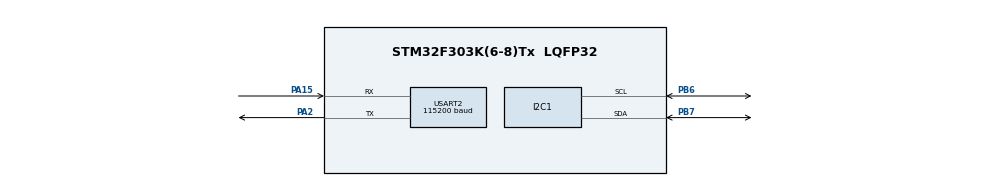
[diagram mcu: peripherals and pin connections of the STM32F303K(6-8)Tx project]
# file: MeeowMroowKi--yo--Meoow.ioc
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Dma.Request0=USART2_RX
Dma.Request1=USART2_TX
Dma.USART2_RX.0.Direction=DMA_PERIPH_TO_MEMORY
Dma.USART2_RX.0.Instance=DMA1_Channel6
Dma.USART2_RX.0.MemDataAlignment=DMA_MDATAALIGN_BYTE
Dma.USART2_RX.0.MemInc=DMA_MINC_ENABLE
Dma.USART2_RX.0.Mode=DMA_CIRCULAR
Dma.USART2_RX.0.PeriphDataAlignment=DMA_PDATAALIGN_BYTE
Dma.USART2_RX.0.PeriphInc=DMA_PINC_DISABLE
Dma.USART2_RX.0.Priority=DMA_PRIORITY_MEDIUM
Dma.USART2_TX.1.Direction=DMA_MEMORY_TO_PERIPH
Dma.USART2_TX.1.Instance=DMA1_Channel7
Dma.USART2_TX.1.MemDataAlignment=DMA_MDATAALIGN_BYTE
Dma.USART2_TX.1.MemInc=DMA_MINC_ENABLE
Dma.USART2_TX.1.Mode=DMA_NORMAL
Dma.USART2_TX.1.PeriphDataAlignment=DMA_PDATAALIGN_BYTE
Dma.USART2_TX.1.PeriphInc=DMA_PINC_DISABLE
Dma.USART2_TX.1.Priority=DMA_PRIORITY_MEDIUM
I2C1.OwnAddress=1
Mcu.Family=STM32F3
Mcu.Name=STM32F303K(6-8)Tx
Mcu.Package=LQFP32
NVIC.DMA1_Channel6_IRQn=true\:0\:0\:false\:false\:true\:false\:true\:true
NVIC.DMA1_Channel7_IRQn=true\:0\:0\:false\:false\:true\:false\:true\:true
NVIC.I2C1_EV_IRQn=true\:0\:0\:false\:false\:true\:true\:true\:true
NVIC.PriorityGroup=NVIC_PRIORITYGROUP_4
NVIC.USART2_IRQn=true\:0\:0\:false\:false\:true\:true\:true\:true
PA15.Mode=Asynchronous
PA15.Signal=USART2_RX
PA2.Mode=Asynchronous
PA2.Signal=USART2_TX
PB6.Mode=I2C
PB6.Signal=I2C1_SCL
PB7.Mode=I2C
PB7.Signal=I2C1_SDA
ProjectManager.HeapSize=0x200
ProjectManager.StackSize=0x400
ProjectManager.TargetToolchain=STM32CubeIDE
RCC.AHBFreq_Value=8000000
RCC.APB1Freq_Value=8000000
RCC.APB2Freq_Value=8000000
RCC.CortexFreq_Value=8000000
RCC.HSE_VALUE=8000000
RCC.HSI_VALUE=8000000
RCC.SYSCLKFreq_VALUE=8000000
USART2.BaudRate=115200
USART2.VirtualMode-Asynchronous=VM_ASYNC
board=custom

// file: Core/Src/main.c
/* USER CODE BEGIN Header */
/**
  ******************************************************************************
  * @file           : main.c
  * @brief          : Main program body
  ******************************************************************************
  * @attention
  *
  * Copyright (c) 2023 STMicroelectronics.
  * All rights reserved.
  *
  * This software is licensed under terms that can be found in the LICENSE file
  * in the root directory of this software component.
  * If no LICENSE file comes with this software, it is provided AS-IS.
  *
  ******************************************************************************
  */
/* USER CODE END Header */
#include "main.h"
#include "stm32f3xx_it.h"
#include "i2cm.h"
#include "tempSensor.h"
#include <string.h>

#include "../../LPS22HB/sensorPress.h"

void SystemClock_Config(void);
static void MX_GPIO_Init(void);
static void MX_DMA_Init(void);
static void MX_USART2_UART_Init(void);
static void MX_I2C1_Init(void);
void USART2_PutBuffer(uint8_t *buffer, uint8_t length);

/* USER CODE BEGIN 0 */
uint32_t bufferMeow[bufferSize];
uint32_t bufferMroow[bufferSize];
uint8_t bufferPaws[bufferSize];
uint32_t *dontPointAtMeMroow = bufferMroow;
/* USER CODE END 0 */

int main(void)
{

  /* MCU Configuration--------------------------------------------------------*/

  /* Reset of all peripherals, Initializes the Flash interface and the Systick. */
  LL_APB2_GRP1_EnableClock(LL_APB2_GRP1_PERIPH_SYSCFG);
  LL_APB1_GRP1_EnableClock(LL_APB1_GRP1_PERIPH_PWR);

  /* System interrupt init*/
  NVIC_SetPriorityGrouping(NVIC_PRIORITYGROUP_4);

  /* SysTick_IRQn interrupt configuration */
  NVIC_SetPriority(SysTick_IRQn, NVIC_EncodePriority(NVIC_GetPriorityGrouping(),15, 0));

  /* Configure the system clock */
  SystemClock_Config();

  /* Initialize all configured peripherals */
  MX_GPIO_Init();
  MX_DMA_Init();
  MX_USART2_UART_Init();
  MX_I2C1_Init();
  callBackFunction(readRegisterMeow,writeRegisterMroow);
  callBackFunctionLP(readRegisterMeow,writeRegisterMroow);
  htsInit();
  LL_mDelay(10);
  lpInit();
  LL_mDelay(10);
  //Activate_I2C1_IT();

  /* Infinite loop */
  while (1)
  {

	 /*
	  *
	  *  urob whoamI pre ten dalsi
	  *  kukni ako hladat data v nich
	  *  asi to bude podla registor... musis precitat pichoviny
	  *  a potom súravne registry pingovat to vse...
	  *
	  *
	  */
	  memset(bufferPaws, 0, bufferSize);
	  LL_mDelay(100);
	  double value = readTemp();
	  LL_mDelay(1);
	  double valueH = readHum();
	  LL_mDelay(1);
	  double valueP = readPress();
	  LL_mDelay(1);
	  double valueA = getAlt(valueP);
	  sprintf((char*)bufferPaws, "temp: %f[C], hum: %f[%%], press %f[hBar], vyska: %f[m] \n \r",value, valueH, valueP,valueA);
	  USART2_PutBuffer(bufferPaws, sizeof(bufferPaws));

	  LL_mDelay(500);
  }
}

void SystemClock_Config(void)
{
  LL_FLASH_SetLatency(LL_FLASH_LATENCY_0);
  while(LL_FLASH_GetLatency()!= LL_FLASH_LATENCY_0)
  {
  }
  LL_RCC_HSI_Enable();

   /* Wait till HSI is ready */
  while(LL_RCC_HSI_IsReady() != 1)
  {

  }
  LL_RCC_HSI_SetCalibTrimming(16);
  LL_RCC_SetAHBPrescaler(LL_RCC_SYSCLK_DIV_1);
  LL_RCC_SetAPB1Prescaler(LL_RCC_APB1_DIV_1);
  LL_RCC_SetAPB2Prescaler(LL_RCC_APB2_DIV_1);
  LL_RCC_SetSysClkSource(LL_RCC_SYS_CLKSOURCE_HSI);

   /* Wait till System clock is ready */
  while(LL_RCC_GetSysClkSource() != LL_RCC_SYS_CLKSOURCE_STATUS_HSI)
  {

  }
  LL_Init1msTick(8000000);
  LL_SetSystemCoreClock(8000000);
  LL_RCC_SetI2CClockSource(LL_RCC_I2C1_CLKSOURCE_HSI);
}

static void MX_I2C1_Init(void)
{

  LL_I2C_InitTypeDef I2C_InitStruct = {0};

  LL_GPIO_InitTypeDef GPIO_InitStruct = {0};

  LL_AHB1_GRP1_EnableClock(LL_AHB1_GRP1_PERIPH_GPIOB);
  /**I2C1 GPIO Configuration
  PB6   ------> I2C1_SCL
  PB7   ------> I2C1_SDA
  */
  GPIO_InitStruct.Pin = LL_GPIO_PIN_6|LL_GPIO_PIN_7;
  GPIO_InitStruct.Mode = LL_GPIO_MODE_ALTERNATE;
  GPIO_InitStruct.Speed = LL_GPIO_SPEED_FREQ_HIGH;
  GPIO_InitStruct.OutputType = LL_GPIO_OUTPUT_OPENDRAIN;
  GPIO_InitStruct.Pull = LL_GPIO_PULL_UP;
  GPIO_InitStruct.Alternate = LL_GPIO_AF_4;
  LL_GPIO_Init(GPIOB, &GPIO_InitStruct);

  /* Peripheral clock enable */
  LL_APB1_GRP1_EnableClock(LL_APB1_GRP1_PERIPH_I2C1);

  /* I2C1 interrupt Init */
  NVIC_SetPriority(I2C1_EV_IRQn, NVIC_EncodePriority(NVIC_GetPriorityGrouping(),0, 0));
  NVIC_EnableIRQ(I2C1_EV_IRQn);

  /** I2C Initialization
  */
  LL_I2C_EnableAutoEndMode(I2C1);
  LL_I2C_DisableOwnAddress2(I2C1);
  LL_I2C_DisableGeneralCall(I2C1);
  LL_I2C_EnableClockStretching(I2C1);
  I2C_InitStruct.PeripheralMode = LL_I2C_MODE_I2C;
  I2C_InitStruct.Timing = 0x2000090E;
  I2C_InitStruct.AnalogFilter = LL_I2C_ANALOGFILTER_ENABLE;
  I2C_InitStruct.DigitalFilter = 0;
  I2C_InitStruct.OwnAddress1 = 2;
  I2C_InitStruct.TypeAcknowledge = LL_I2C_ACK;
  I2C_InitStruct.OwnAddrSize = LL_I2C_OWNADDRESS1_7BIT;
  LL_I2C_Init(I2C1, &I2C_InitStruct);
  LL_I2C_SetOwnAddress2(I2C1, 0, LL_I2C_OWNADDRESS2_NOMASK);
  /* USER CODE BEGIN I2C1_Init 2 */
  LL_I2C_SetMode(I2C1, LL_I2C_MODE_I2C);
  //LL_I2C_Enable(I2C1);
  LL_I2C_Enable(I2C1);
  /* USER CODE END I2C1_Init 2 */

}

static void MX_USART2_UART_Init(void)
{

  LL_USART_InitTypeDef USART_InitStruct = {0};

  LL_GPIO_InitTypeDef GPIO_InitStruct = {0};

  /* Peripheral clock enable */
  LL_APB1_GRP1_EnableClock(LL_APB1_GRP1_PERIPH_USART2);

  LL_AHB1_GRP1_EnableClock(LL_AHB1_GRP1_PERIPH_GPIOA);
  /**USART2 GPIO Configuration
  PA2   ------> USART2_TX
  PA15   ------> USART2_RX
  */
  GPIO_InitStruct.Pin = LL_GPIO_PIN_2|LL_GPIO_PIN_15;
  GPIO_InitStruct.Mode = LL_GPIO_MODE_ALTERNATE;
  GPIO_InitStruct.Speed = LL_GPIO_SPEED_FREQ_HIGH;
  GPIO_InitStruct.OutputType = LL_GPIO_OUTPUT_PUSHPULL;
  GPIO_InitStruct.Pull = LL_GPIO_PULL_NO;
  GPIO_InitStruct.Alternate = LL_GPIO_AF_7;
  LL_GPIO_Init(GPIOA, &GPIO_InitStruct);

  /* USART2 DMA Init */

  /* USART2_RX Init */
  LL_DMA_SetDataTransferDirection(DMA1, LL_DMA_CHANNEL_6, LL_DMA_DIRECTION_PERIPH_TO_MEMORY);
  LL_DMA_SetChannelPriorityLevel(DMA1, LL_DMA_CHANNEL_6, LL_DMA_PRIORITY_MEDIUM);
  LL_DMA_SetMode(DMA1, LL_DMA_CHANNEL_6, LL_DMA_MODE_CIRCULAR);
  LL_DMA_SetPeriphIncMode(DMA1, LL_DMA_CHANNEL_6, LL_DMA_PERIPH_NOINCREMENT);
  LL_DMA_SetMemoryIncMode(DMA1, LL_DMA_CHANNEL_6, LL_DMA_MEMORY_INCREMENT);
  LL_DMA_SetPeriphSize(DMA1, LL_DMA_CHANNEL_6, LL_DMA_PDATAALIGN_BYTE);
  LL_DMA_SetMemorySize(DMA1, LL_DMA_CHANNEL_6, LL_DMA_MDATAALIGN_BYTE);

  LL_DMA_ConfigAddresses(	DMA1, LL_DMA_CHANNEL_6,
						 	LL_USART_DMA_GetRegAddr(USART2, LL_USART_DMA_REG_DATA_RECEIVE),
							(uint32_t)bufferMeow,
							LL_DMA_GetDataTransferDirection(DMA1, LL_DMA_CHANNEL_6));

  LL_DMA_SetDataLength(DMA1, LL_DMA_CHANNEL_6, bufferSize);
  LL_DMA_EnableChannel(DMA1, LL_DMA_CHANNEL_6);
  LL_USART_EnableDMAReq_RX(USART2);

  /* USART2_TX Init */
  LL_DMA_SetDataTransferDirection(DMA1, LL_DMA_CHANNEL_7, LL_DMA_DIRECTION_MEMORY_TO_PERIPH);
  LL_DMA_SetChannelPriorityLevel(DMA1, LL_DMA_CHANNEL_7, LL_DMA_PRIORITY_MEDIUM);
  LL_DMA_SetMode(DMA1, LL_DMA_CHANNEL_7, LL_DMA_MODE_NORMAL);
  LL_DMA_SetPeriphIncMode(DMA1, LL_DMA_CHANNEL_7, LL_DMA_PERIPH_NOINCREMENT);
  LL_DMA_SetMemoryIncMode(DMA1, LL_DMA_CHANNEL_7, LL_DMA_MEMORY_INCREMENT);
  LL_DMA_SetPeriphSize(DMA1, LL_DMA_CHANNEL_7, LL_DMA_PDATAALIGN_BYTE);
  LL_DMA_SetMemorySize(DMA1, LL_DMA_CHANNEL_7, LL_DMA_MDATAALIGN_BYTE);

  LL_DMA_SetPeriphAddress(DMA1, LL_DMA_CHANNEL_7, LL_USART_DMA_GetRegAddr(USART2, LL_USART_DMA_REG_DATA_TRANSMIT));
  LL_USART_EnableDMAReq_TX(USART2);

  /* USART2 interrupt Init */
  NVIC_SetPriority(USART2_IRQn, NVIC_EncodePriority(NVIC_GetPriorityGrouping(),0, 0));
  NVIC_EnableIRQ(USART2_IRQn);

  USART_InitStruct.BaudRate = 115200;
  USART_InitStruct.DataWidth = LL_USART_DATAWIDTH_8B;
  USART_InitStruct.StopBits = LL_USART_STOPBITS_1;
  USART_InitStruct.Parity = LL_USART_PARITY_NONE;
  USART_InitStruct.TransferDirection = LL_USART_DIRECTION_TX_RX;
  USART_InitStruct.HardwareFlowControl = LL_USART_HWCONTROL_NONE;
  USART_InitStruct.OverSampling = LL_USART_OVERSAMPLING_16;
  LL_USART_Init(USART2, &USART_InitStruct);
  LL_USART_DisableIT_CTS(USART2);
  LL_USART_ConfigAsyncMode(USART2);
  LL_USART_Enable(USART2);

}

static void MX_DMA_Init(void)
{

  /* Init with LL driver */
  /* DMA controller clock enable */
  LL_AHB1_GRP1_EnableClock(LL_AHB1_GRP1_PERIPH_DMA1);

  /* DMA interrupt init */
  /* DMA1_Channel6_IRQn interrupt configuration */
  NVIC_SetPriority(DMA1_Channel6_IRQn, NVIC_EncodePriority(NVIC_GetPriorityGrouping(),0, 0));
  NVIC_EnableIRQ(DMA1_Channel6_IRQn);
  /* DMA1_Channel7_IRQn interrupt configuration */
  NVIC_SetPriority(DMA1_Channel7_IRQn, NVIC_EncodePriority(NVIC_GetPriorityGrouping(),0, 0));
  NVIC_EnableIRQ(DMA1_Channel7_IRQn);

}

static void MX_GPIO_Init(void)
{

  /* GPIO Ports Clock Enable */
  LL_AHB1_GRP1_EnableClock(LL_AHB1_GRP1_PERIPH_GPIOA);
  LL_AHB1_GRP1_EnableClock(LL_AHB1_GRP1_PERIPH_GPIOB);

}

/* USER CODE BEGIN 4 */

void USART2_PutBuffer(uint8_t *buffer, uint8_t length)
{
	LL_DMA_SetMemoryAddress(DMA1, LL_DMA_CHANNEL_7, (uint32_t)buffer);
	LL_DMA_SetDataLength(DMA1, LL_DMA_CHANNEL_7, length);
	LL_DMA_EnableIT_TC(DMA1, LL_DMA_CHANNEL_7);
	LL_DMA_EnableChannel(DMA1, LL_DMA_CHANNEL_7);

}

/* USER CODE END 4 */

void Error_Handler(void)
{
  __disable_irq();
  while (1)
  {
  }
}
